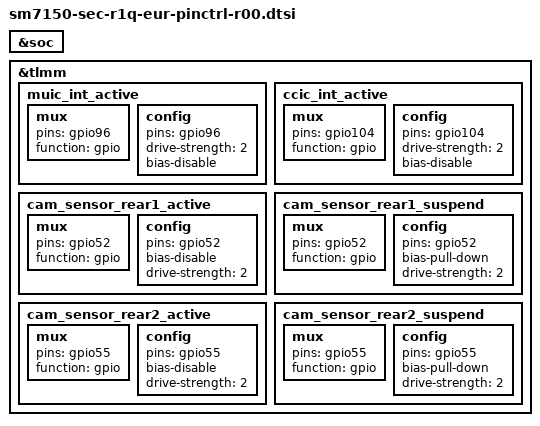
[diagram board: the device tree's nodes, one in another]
/* Copyright (c) 2018, The Linux Foundation. All rights reserved.
 *
 * This program is free software; you can redistribute it and/or modify
 * it under the terms of the GNU General Public License version 2 and
 * only version 2 as published by the Free Software Foundation.
 *
 * This program is distributed in the hope that it will be useful,
 * but WITHOUT ANY WARRANTY; without even the implied warranty of
 * MERCHANTABILITY or FITNESS FOR A PARTICULAR PURPOSE.  See the
 * GNU General Public License for more details.
 */

#include "sm7150-sec-r1q-pinctrl-common.dtsi"

&soc {
	
};

&tlmm {
	muic_int_active: muic_int_active {
		mux {
			pins = "gpio96";
	 		function = "gpio";
	 	};
		config {
	 		pins = "gpio96";
			drive-strength = <2>;
			bias-disable;

	 	};
	};

	ccic_int_active: ccic_int_active {
		mux {
			pins = "gpio104";
	 		function = "gpio";
	 	};
		config {
	 		pins = "gpio104";
			drive-strength = <2>;
			bias-disable;

	 	};
	};

	cam_sensor_rear1_active: cam_sensor_rear1_active {
		/* RESET REAR1 */
		mux {
			pins = "gpio52";
			function = "gpio";
		};
		config {
			pins = "gpio52";
			bias-disable; /* No PULL */
			drive-strength = <2>; /* 2 MA */
		};
	};
	
	cam_sensor_rear1_suspend: cam_sensor_rear1_suspend {
		/* REAR1 RESET */
		mux {
			pins = "gpio52";
			function = "gpio";
		};
		config {
			pins = "gpio52";
			bias-pull-down; /* PULL DOWN */
			drive-strength = <2>; /* 2 MA */
		};
	};
	
	cam_sensor_rear2_active: cam_sensor_rear2_active {
		/* RESET REAR2 */
		mux {
			pins = "gpio55";
			function = "gpio";
		};
		config {
			pins = "gpio55";
			bias-disable; /* No PULL */
			drive-strength = <2>; /* 2 MA */
		};
	};
	
	cam_sensor_rear2_suspend: cam_sensor_rear2_suspend {
		/* REAR2 RESET */
		mux {
			pins = "gpio55";
			function = "gpio";
		};
		config {
			pins = "gpio55";
			bias-pull-down; /* PULL DOWN */
			drive-strength = <2>; /* 2 MA */
		};
	};	
};
